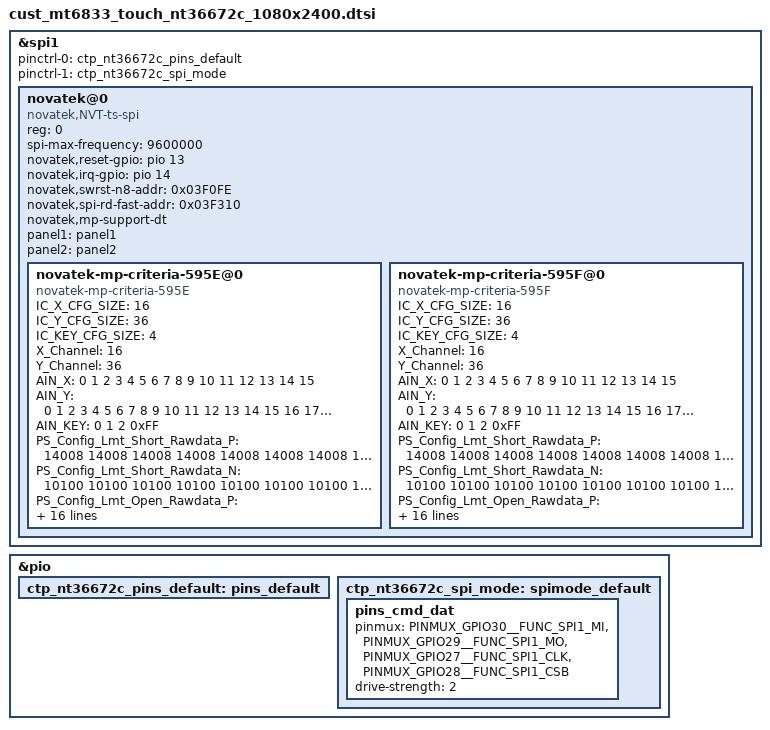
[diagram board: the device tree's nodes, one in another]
/*
 * Copyright (c) 2019 MediaTek Inc.
 *
 * This program is free software; you can redistribute it and/or modify
 * it under the terms of the GNU General Public License version 2 as
 * published by the Free Software Foundation.
 *
 * This program is distributed in the hope that it will be useful,
 * but WITHOUT ANY WARRANTY; without even the implied warranty of
 * MERCHANTABILITY or FITNESS FOR A PARTICULAR PURPOSE.  See the
 * GNU General Public License for more details.
 */

/* TOUCH start */
&spi1 {
	status = "okay";
	#address-cells = <1>;
	#size-cells = <0>;
	pinctrl-names = "default", "nt36672c_spi_mode";
	pinctrl-0 = <&ctp_nt36672c_pins_default>;
	pinctrl-1 = <&ctp_nt36672c_spi_mode>;

	/* Novatek device tree node */
	novatek@0 {
		compatible = "novatek,NVT-ts-spi";
		reg = <0>; //Same as CS ID
		status = "okay";
		//4800000,9600000,15000000,19200000
		spi-max-frequency = <9600000>;

		novatek,reset-gpio = <&pio 13 0x00>;
		novatek,irq-gpio = <&pio 14 0x00>;

		/* 525 */
		//novatek,swrst-n8-addr = <0x01F01A>;

		/* 672A, 525B, 675, 526 */
		novatek,swrst-n8-addr = <0x03F0FE>;
		novatek,spi-rd-fast-addr = <0x03F310>;

		/* MP */
		novatek,mp-support-dt;
		panel1 = <&panel1>;
		panel2 = <&panel2>;

		novatek-mp-criteria-595E@0 { //PID 为595E ，TM
			#address-cells = <1>;
			#size-cells = <0>;
			compatible = "novatek-mp-criteria-595E";

			/* MP Config */
			IC_X_CFG_SIZE = <16>;
			IC_Y_CFG_SIZE = <36>;
			IC_KEY_CFG_SIZE = <4>;
			X_Channel = <16>;
			Y_Channel = <36>;
			AIN_X = <0 1 2 3 4 5 6 7 8 9 10 11 12 13 14 15 >;
			AIN_Y = <0 1 2 3 4 5 6 7 8 9 10 11 12 13 14 15 16 17
			18 19 20 21 22 23 24 25 26 27 28 29 30 31 32 33 34 35>;
			AIN_KEY = <0 1 2 0xFF>;

			/* MP Criteria */
			PS_Config_Lmt_Short_Rawdata_P = <
			  14008 14008 14008 14008 14008 14008 14008 14008 14008 14008 14008 14008 14008 14008 14008 14008
			  14008 14008 14008 14008 14008 14008 14008 14008 14008 14008 14008 14008 14008 14008 14008 14008
			  14008 14008 14008 14008 14008 14008 14008 14008 14008 14008 14008 14008 14008 14008 14008 14008
			  14008 14008 14008 14008 14008 14008 14008 14008 14008 14008 14008 14008 14008 14008 14008 14008
			  14008 14008 14008 14008 14008 14008 14008 14008 14008 14008 14008 14008 14008 14008 14008 14008
			  14008 14008 14008 14008 14008 14008 14008 14008 14008 14008 14008 14008 14008 14008 14008 14008
			  14008 14008 14008 14008 14008 14008 14008 14008 14008 14008 14008 14008 14008 14008 14008 14008
			  14008 14008 14008 14008 14008 14008 14008 14008 14008 14008 14008 14008 14008 14008 14008 14008
			  14008 14008 14008 14008 14008 14008 14008 14008 14008 14008 14008 14008 14008 14008 14008 14008
			  14008 14008 14008 14008 14008 14008 14008 14008 14008 14008 14008 14008 14008 14008 14008 14008
			  14008 14008 14008 14008 14008 14008 14008 14008 14008 14008 14008 14008 14008 14008 14008 14008
			  14008 14008 14008 14008 14008 14008 14008 14008 14008 14008 14008 14008 14008 14008 14008 14008
			  14008 14008 14008 14008 14008 14008 14008 14008 14008 14008 14008 14008 14008 14008 14008 14008
			  14008 14008 14008 14008 14008 14008 14008 14008 14008 14008 14008 14008 14008 14008 14008 14008
			  14008 14008 14008 14008 14008 14008 14008 14008 14008 14008 14008 14008 14008 14008 14008 14008
			  14008 14008 14008 14008 14008 14008 14008 14008 14008 14008 14008 14008 14008 14008 14008 14008
			  14008 14008 14008 14008 14008 14008 14008 14008 14008 14008 14008 14008 14008 14008 14008 14008
			  14008 14008 14008 14008 14008 14008 14008 14008 14008 14008 14008 14008 14008 14008 14008 14008
			  14008 14008 14008 14008 14008 14008 14008 14008 14008 14008 14008 14008 14008 14008 14008 14008
			  14008 14008 14008 14008 14008 14008 14008 14008 14008 14008 14008 14008 14008 14008 14008 14008
			  14008 14008 14008 14008 14008 14008 14008 14008 14008 14008 14008 14008 14008 14008 14008 14008
			  14008 14008 14008 14008 14008 14008 14008 14008 14008 14008 14008 14008 14008 14008 14008 14008
			  14008 14008 14008 14008 14008 14008 14008 14008 14008 14008 14008 14008 14008 14008 14008 14008
			  14008 14008 14008 14008 14008 14008 14008 14008 14008 14008 14008 14008 14008 14008 14008 14008
			  14008 14008 14008 14008 14008 14008 14008 14008 14008 14008 14008 14008 14008 14008 14008 14008
			  14008 14008 14008 14008 14008 14008 14008 14008 14008 14008 14008 14008 14008 14008 14008 14008
			  14008 14008 14008 14008 14008 14008 14008 14008 14008 14008 14008 14008 14008 14008 14008 14008
			  14008 14008 14008 14008 14008 14008 14008 14008 14008 14008 14008 14008 14008 14008 14008 14008
			  14008 14008 14008 14008 14008 14008 14008 14008 14008 14008 14008 14008 14008 14008 14008 14008
			  14008 14008 14008 14008 14008 14008 14008 14008 14008 14008 14008 14008 14008 14008 14008 14008
			  14008 14008 14008 14008 14008 14008 14008 14008 14008 14008 14008 14008 14008 14008 14008 14008
			  14008 14008 14008 14008 14008 14008 14008 14008 14008 14008 14008 14008 14008 14008 14008 14008
			  14008 14008 14008 14008 14008 14008 14008 14008 14008 14008 14008 14008 14008 14008 14008 14008
			  14008 14008 14008 14008 14008 14008 14008 14008 14008 14008 14008 14008 14008 14008 14008 14008
			  14008 14008 14008 14008 14008 14008 14008 14008 14008 14008 14008 14008 14008 14008 14008 14008
			  14008 14008 14008 14008 14008 14008 14008 14008 14008 14008 14008 14008 14008 14008 14008 14008
			  14008 14008 14008>;

			PS_Config_Lmt_Short_Rawdata_N = <
			  10100 10100 10100 10100 10100 10100 10100 10100 10100 10100 10100 10100 10100 10100 10100 10100
			  10100 10100 10100 10100 10100 10100 10100 10100 10100 10100 10100 10100 10100 10100 10100 10100
			  10100 10100 10100 10100 10100 10100 10100 10100 10100 10100 10100 10100 10100 10100 10100 10100
			  10100 10100 10100 10100 10100 10100 10100 10100 10100 10100 10100 10100 10100 10100 10100 10100
			  10100 10100 10100 10100 10100 10100 10100 10100 10100 10100 10100 10100 10100 10100 10100 10100
			  10100 10100 10100 10100 10100 10100 10100 10100 10100 10100 10100 10100 10100 10100 10100 10100
			  10100 10100 10100 10100 10100 10100 10100 10100 10100 10100 10100 10100 10100 10100 10100 10100
			  10100 10100 10100 10100 10100 10100 10100 10100 10100 10100 10100 10100 10100 10100 10100 10100
			  10100 10100 10100 10100 10100 10100 10100 10100 10100 10100 10100 10100 10100 10100 10100 10100
			  10100 10100 10100 10100 10100 10100 10100 10100 10100 10100 10100 10100 10100 10100 10100 10100
			  10100 10100 10100 10100 10100 10100 10100 10100 10100 10100 10100 10100 10100 10100 10100 10100
			  10100 10100 10100 10100 10100 10100 10100 10100 10100 10100 10100 10100 10100 10100 10100 10100
			  10100 10100 10100 10100 10100 10100 10100 10100 10100 10100 10100 10100 10100 10100 10100 10100
			  10100 10100 10100 10100 10100 10100 10100 10100 10100 10100 10100 10100 10100 10100 10100 10100
			  10100 10100 10100 10100 10100 10100 10100 10100 10100 10100 10100 10100 10100 10100 10100 10100
			  10100 10100 10100 10100 10100 10100 10100 10100 10100 10100 10100 10100 10100 10100 10100 10100
			  10100 10100 10100 10100 10100 10100 10100 10100 10100 10100 10100 10100 10100 10100 10100 10100
			  10100 10100 10100 10100 10100 10100 10100 10100 10100 10100 10100 10100 10100 10100 10100 10100
			  10100 10100 10100 10100 10100 10100 10100 10100 10100 10100 10100 10100 10100 10100 10100 10100
			  10100 10100 10100 10100 10100 10100 10100 10100 10100 10100 10100 10100 10100 10100 10100 10100
			  10100 10100 10100 10100 10100 10100 10100 10100 10100 10100 10100 10100 10100 10100 10100 10100
			  10100 10100 10100 10100 10100 10100 10100 10100 10100 10100 10100 10100 10100 10100 10100 10100
			  10100 10100 10100 10100 10100 10100 10100 10100 10100 10100 10100 10100 10100 10100 10100 10100
			  10100 10100 10100 10100 10100 10100 10100 10100 10100 10100 10100 10100 10100 10100 10100 10100
			  10100 10100 10100 10100 10100 10100 10100 10100 10100 10100 10100 10100 10100 10100 10100 10100
			  10100 10100 10100 10100 10100 10100 10100 10100 10100 10100 10100 10100 10100 10100 10100 10100
			  10100 10100 10100 10100 10100 10100 10100 10100 10100 10100 10100 10100 10100 10100 10100 10100
			  10100 10100 10100 10100 10100 10100 10100 10100 10100 10100 10100 10100 10100 10100 10100 10100
			  10100 10100 10100 10100 10100 10100 10100 10100 10100 10100 10100 10100 10100 10100 10100 10100
			  10100 10100 10100 10100 10100 10100 10100 10100 10100 10100 10100 10100 10100 10100 10100 10100
			  10100 10100 10100 10100 10100 10100 10100 10100 10100 10100 10100 10100 10100 10100 10100 10100
			  10100 10100 10100 10100 10100 10100 10100 10100 10100 10100 10100 10100 10100 10100 10100 10100
			  10100 10100 10100 10100 10100 10100 10100 10100 10100 10100 10100 10100 10100 10100 10100 10100
			  10100 10100 10100 10100 10100 10100 10100 10100 10100 10100 10100 10100 10100 10100 10100 10100
			  10100 10100 10100 10100 10100 10100 10100 10100 10100 10100 10100 10100 10100 10100 10100 10100
			  10100 10100 10100 10100 10100 10100 10100 10100 10100 10100 10100 10100 10100 10100 10100 10100
			  10000 10000 10000>;

			PS_Config_Lmt_Open_Rawdata_P = <
			  4208 4327 4419 4670 4583 4650 4572 4468 4379 4575 4583 4621 4639 4460 4335 4284
			  4403 4543 4580 4701 4624 4684 4590 4540 4403 4593 4607 4646 4656 4638 4536 4506
			  4540 4594 4648 4797 4727 4765 4747 4775 4701 4746 4695 4734 4762 4687 4600 4572
			  4578 4587 4683 4841 4761 4799 4771 4796 4727 4740 4716 4757 4769 4699 4600 4580
			  4628 4698 4723 4895 4831 4872 4821 4855 4797 4866 4771 4828 4816 4741 4635 4622
			  4636 4699 4697 4898 4844 4895 4832 4866 4792 4855 4720 4813 4793 4719 4624 4607
			  4655 4720 4778 4918 4873 4932 4860 4893 4855 4912 4834 4858 4820 4767 4649 4636
			  4649 4722 4785 4879 4888 4950 4866 4894 4872 4918 4846 4844 4813 4754 4650 4625
			  4719 4783 4838 4979 4964 5010 4940 4957 4963 4999 4928 4974 4867 4811 4713 4674
			  4734 4789 4842 4991 4951 5020 4947 4954 4970 5003 4923 4977 4832 4796 4691 4660
			  4730 4804 4848 5013 5017 5017 4963 4998 4988 5047 4956 5027 4883 4782 4701 4681
			  4769 4845 4879 5044 5052 5101 4996 5017 4984 5042 4954 5034 4886 4832 4704 4680
			  4796 4858 4911 5062 5104 5160 5007 5044 5031 5079 5012 5061 4907 4862 4690 4684
			  4782 4846 4904 5038 5096 5154 5048 5020 5055 5104 5037 5097 4907 4872 4748 4691
			  4849 4909 4963 5100 5160 5222 5132 5052 5129 5159 5077 5145 4963 4894 4788 4680
			  4851 4915 4957 5086 5161 5219 5145 5115 5154 5175 5100 5166 4958 4895 4782 4712
			  4860 4932 4946 5086 5167 5243 5139 5133 5181 5220 5124 5202 4975 4918 4783 4732
			  4855 4932 4930 5073 5161 5234 5145 5139 5163 5205 5111 5178 4956 4904 4750 4711
			  4758 4722 4662 4669 4579 4606 4594 4653 4529 4639 4617 4634 4638 4740 4741 4907
			  4762 4751 4669 4677 4596 4625 4606 4673 4534 4632 4629 4646 4655 4750 4744 4901
			  4771 4778 4698 4699 4622 4648 4631 4688 4573 4678 4671 4690 4687 4793 4775 4890
			  4774 4778 4701 4701 4614 4643 4632 4678 4562 4678 4680 4701 4698 4792 4762 4881
			  4786 4813 4716 4716 4652 4666 4650 4692 4597 4704 4690 4746 4732 4804 4781 4881
			  4797 4832 4733 4750 4660 4677 4666 4706 4603 4690 4685 4736 4727 4792 4771 4860
			  4769 4821 4727 4736 4655 4676 4655 4697 4618 4713 4699 4747 4741 4824 4790 4873
			  4778 4841 4743 4751 4669 4708 4677 4725 4624 4698 4685 4734 4729 4811 4776 4837
			  4760 4827 4741 4747 4667 4688 4681 4723 4643 4716 4720 4760 4761 4831 4820 4845
			  4758 4825 4744 4744 4670 4697 4685 4720 4628 4692 4687 4730 4719 4799 4778 4795
			  4772 4866 4765 4796 4699 4732 4718 4757 4650 4723 4698 4758 4744 4820 4797 4797
			  4743 4823 4734 4768 4674 4702 4698 4729 4627 4691 4660 4716 4709 4779 4753 4757
			  4722 4817 4748 4769 4676 4716 4698 4726 4632 4709 4691 4726 4718 4806 4743 4750
			  4356 4796 4370 4762 4312 4725 4326 4716 4281 4708 4314 4720 4344 4797 4359 4736
			  4383 4440 4405 4428 4351 4394 4366 4387 4317 4377 4344 4382 4369 4432 4375 4384
			  4376 4428 4403 4429 4345 4387 4359 4383 4324 4386 4338 4383 4363 4426 4363 4375
			  4225 4348 4320 4349 4271 4314 4279 4312 4250 4323 4260 4313 4292 4356 4279 4239
			  3880 3943 3990 4382 4295 4337 4303 4338 4254 4331 4265 4312 4295 4018 3858 3876
			  5120  5120  5120>;

			PS_Config_Lmt_Open_Rawdata_N = <
			  1803 1854 1894 2001 1964 1993 1959 1915 1876 1960 1964 1980 1988 1911 1858 1836
			  1887 1947 1963 2014 1981 2007 1967 1945 1887 1968 1974 1991 1995 1987 1944 1931
			  1945 1969 1992 2056 2026 2042 2034 2046 2014 2034 2012 2029 2041 2008 1971 1959
			  1962 1966 2007 2074 2040 2056 2044 2055 2026 2031 2021 2038 2044 2014 1971 1963
			  1983 2013 2024 2098 2070 2088 2066 2080 2056 2085 2044 2069 2064 2032 1986 1981
			  1987 2014 2013 2099 2076 2098 2071 2085 2053 2080 2023 2062 2054 2022 1981 1974
			  1995 2023 2047 2107 2088 2113 2083 2097 2080 2105 2071 2082 2065 2043 1992 1987
			  1992 2023 2050 2091 2095 2121 2085 2097 2088 2107 2077 2076 2062 2037 1993 1982
			  2022 2050 2073 2134 2127 2147 2117 2124 2127 2142 2112 2131 2086 2062 2020 2003
			  2029 2052 2075 2139 2122 2151 2120 2123 2130 2144 2110 2133 2071 2055 2010 1997
			  2027 2059 2077 2148 2150 2150 2127 2142 2137 2163 2124 2154 2092 2049 2014 2006
			  2044 2076 2091 2161 2165 2186 2141 2150 2136 2161 2123 2157 2094 2071 2016 2005
			  2055 2082 2104 2169 2187 2211 2146 2161 2156 2176 2148 2169 2103 2083 2010 2007
			  2049 2077 2101 2159 2184 2209 2163 2151 2166 2187 2158 2184 2103 2088 2035 2010
			  2078 2104 2127 2185 2211 2238 2199 2165 2198 2211 2176 2205 2127 2097 2052 2005
			  2079 2106 2124 2179 2212 2236 2205 2192 2209 2218 2185 2214 2125 2098 2049 2019
			  2083 2113 2119 2179 2214 2247 2202 2200 2220 2237 2196 2229 2132 2107 2050 2028
			  2080 2113 2113 2174 2212 2243 2205 2202 2212 2230 2190 2219 2124 2101 2035 2019
			  2039 2023 1998 2001 1962 1974 1969 1994 1941 1988 1978 1986 1987 2031 2032 2103
			  2041 2036 2001 2004 1969 1982 1974 2002 1943 1985 1984 1991 1995 2035 2033 2100
			  2044 2047 2013 2014 1981 1992 1984 2009 1960 2005 2002 2010 2008 2054 2046 2095
			  2046 2047 2014 2014 1977 1990 1985 2005 1955 2005 2005 2014 2013 2053 2041 2092
			  2051 2062 2021 2021 1993 1999 1993 2011 1970 2016 2010 2034 2028 2059 2049 2092
			  2056 2071 2028 2035 1997 2004 1999 2017 1972 2010 2008 2029 2026 2053 2044 2083
			  2044 2066 2026 2029 1995 2004 1995 2013 1979 2020 2014 2034 2032 2067 2053 2088
			  2047 2074 2032 2036 2001 2017 2004 2025 1981 2013 2008 2029 2026 2062 2047 2073
			  2040 2068 2032 2034 2000 2009 2006 2024 1990 2021 2023 2040 2040 2070 2065 2076
			  2039 2068 2033 2033 2001 2013 2008 2023 1983 2011 2008 2027 2022 2056 2047 2055
			  2045 2085 2042 2055 2014 2028 2022 2038 1993 2024 2013 2039 2033 2065 2056 2056
			  2032 2067 2029 2043 2003 2015 2013 2026 1983 2010 1997 2021 2018 2048 2037 2038
			  2023 2064 2035 2044 2004 2021 2013 2025 1985 2018 2010 2025 2022 2059 2032 2035
			  1867 2055 1873 2041 1848 2025 1854 2021 1834 2017 1849 2023 1861 2056 1868 2029
			  1878 1903 1888 1897 1864 1883 1871 1880 1850 1876 1861 1878 1872 1899 1875 1879
			  1875 1897 1887 1898 1862 1880 1868 1878 1853 1879 1859 1878 1870 1897 1870 1875
			  1810 1863 1851 1864 1830 1849 1834 1848 1821 1852 1825 1848 1839 1867 1834 1816
			  1663 1690 1710 1878 1840 1858 1844 1859 1823 1856 1828 1848 1840 1722 1653 1661
			  (-511) (-511) (-511)>;

			PS_Config_Lmt_FW_Rawdata_P = <
			  1122 1107 1121 1108 1128 1117 1127 1128 1124 1107 1106 1111 1104 1136 1103 1127
			  1120 1124 1120 1124 1113 1122 1120 1122 1127 1128 1125 1121 1125 1128 1129 1111
			  1103 1128 1127 1121 1132 1124 1129 1108 1125 1124 1122 1118 1125 1124 1120 1129
			  1121 1111 1120 1117 1114 1118 1117 1122 1127 1125 1113 1127 1117 1111 1115 1124
			  1121 1120 1113 1117 1114 1115 1117 1128 1122 1124 1128 1135 1125 1122 1114 1129
			  1108 1122 1125 1122 1120 1124 1122 1113 1122 1124 1122 1122 1120 1127 1122 1106
			  1127 1115 1118 1120 1120 1118 1118 1122 1113 1110 1108 1108 1114 1113 1114 1107
			  1111 1121 1113 1113 1113 1114 1113 1127 1127 1131 1141 1138 1138 1124 1118 1103
			  1129 1121 1121 1115 1117 1117 1117 1124 1115 1111 1120 1117 1118 1121 1124 1117
			  1113 1113 1115 1120 1121 1122 1120 1113 1108 1110 1121 1121 1118 1129 1122 1108
			  1113 1108 1111 1106 1113 1114 1111 1124 1121 1120 1131 1125 1127 1121 1113 1121
			  1121 1125 1127 1118 1120 1132 1122 1113 1117 1113 1118 1120 1120 1120 1121 1121
			  1104 1120 1118 1114 1114 1108 1113 1121 1120 1124 1122 1120 1121 1118 1117 1115
			  1114 1114 1115 1120 1122 1114 1117 1122 1111 1110 1120 1120 1122 1121 1121 1113
			  1132 1120 1122 1125 1122 1131 1129 1108 1121 1118 1115 1113 1114 1124 1124 1121
			  1121 1120 1121 1113 1118 1117 1117 1118 1111 1108 1115 1110 1117 1128 1129 1114
			  1113 1122 1120 1113 1114 1118 1111 1128 1118 1128 1127 1120 1110 1111 1113 1124
			  1121 1111 1122 1122 1121 1114 1120 1122 1104 1114 1115 1110 1127 1127 1125 1122
			  1114 1124 1128 1121 1128 1111 1115 1118 1118 1115 1117 1117 1115 1120 1113 1117
			  1108 1113 1115 1118 1111 1115 1115 1122 1106 1120 1127 1120 1118 1118 1115 1120
			  1125 1114 1122 1107 1122 1110 1101 1103 1127 1125 1124 1110 1113 1108 1108 1128
			  1111 1128 1117 1124 1120 1125 1127 1125 1113 1124 1122 1127 1125 1124 1121 1117
			  1114 1122 1120 1125 1121 1120 1118 1117 1127 1127 1127 1121 1127 1124 1118 1111
			  1118 1114 1113 1114 1114 1113 1120 1121 1113 1124 1125 1122 1127 1125 1120 1117
			  1117 1111 1114 1106 1120 1117 1110 1117 1121 1120 1117 1115 1115 1117 1113 1127
			  1120 1113 1113 1118 1118 1120 1122 1115 1122 1120 1120 1117 1121 1120 1120 1121
			  1110 1124 1127 1127 1121 1124 1127 1122 1107 1110 1107 1113 1114 1115 1117 1122
			  1121 1121 1121 1120 1118 1120 1113 1110 1114 1122 1121 1117 1115 1120 1110 1110
			  1129 1108 1108 1111 1113 1113 1121 1124 1114 1114 1113 1117 1115 1111 1113 1128
			  1113 1122 1127 1121 1121 1121 1127 1120 1121 1124 1122 1122 1120 1121 1122 1114
			  1115 1117 1107 1124 1122 1124 1114 1111 1118 1122 1120 1114 1111 1118 1115 1127
			  1108 1122 1124 1121 1128 1124 1127 1122 1108 1110 1127 1113 1131 1117 1120 1115
			  1120 1124 1128 1117 1128 1122 1128 1124 1121 1118 1121 1125 1125 1118 1121 1115
			  1117 1115 1118 1114 1115 1114 1121 1124 1125 1125 1124 1125 1120 1117 1114 1107
			  1128 1118 1118 1115 1117 1118 1117 1118 1118 1117 1117 1117 1120 1115 1120 1115
			  1117 1114 1107 1121 1122 1124 1125 1117 1111 1127 1128 1131 1128 1107 1106 1113
			  3840 3840  3840>;

			PS_Config_Lmt_FW_Rawdata_N = <
			  481 474 480 475 483 478 483 483 481 474 474 476 473 487 472 483
			  480 481 480 481 477 481 480 481 483 483 482 480 482 483 484 476
			  472 483 483 480 485 481 484 475 482 481 481 479 482 481 480 484
			  480 476 480 478 477 479 478 481 483 482 477 483 478 476 478 481
			  480 480 477 478 477 478 478 483 481 481 483 486 482 481 477 484
			  475 481 482 481 480 481 481 477 481 481 481 481 480 483 481 474
			  483 478 479 480 480 479 479 481 477 475 475 475 477 477 477 474
			  476 480 477 477 477 477 477 483 483 484 489 487 487 481 479 472
			  484 480 480 478 478 478 478 481 478 476 480 478 479 480 481 478
			  477 477 478 480 480 481 480 477 475 475 480 480 479 484 481 475
			  477 475 476 474 477 477 476 481 480 480 484 482 483 480 477 480
			  480 482 483 479 480 485 481 477 478 477 479 480 480 480 480 480
			  473 480 479 477 477 475 477 480 480 481 481 480 480 479 478 478
			  477 477 478 480 481 477 478 481 476 475 480 480 481 480 480 477
			  485 480 481 482 481 484 484 475 480 479 478 477 477 481 481 480
			  480 480 480 477 479 478 478 479 476 475 478 475 478 483 484 477
			  477 481 480 477 477 479 476 483 479 483 483 480 475 476 477 481
			  480 476 481 481 480 477 480 481 473 477 478 475 483 483 482 481
			  477 481 483 480 483 476 478 479 479 478 478 478 478 480 477 478
			  475 477 478 479 476 478 478 481 474 480 483 480 479 479 478 480
			  482 477 481 474 481 475 472 472 483 482 481 475 477 475 475 483
			  476 483 478 481 480 482 483 482 477 481 481 483 482 481 480 478
			  477 481 480 482 480 480 479 478 483 483 483 480 483 481 479 476
			  479 477 477 477 477 477 480 480 477 481 482 481 483 482 480 478
			  478 476 477 474 480 478 475 478 480 480 478 478 478 478 477 483
			  480 477 477 479 479 480 481 478 481 480 480 478 480 480 480 480
			  475 481 483 483 480 481 483 481 474 475 474 477 477 478 478 481
			  480 480 480 480 479 480 477 475 477 481 480 478 478 480 475 475
			  484 475 475 476 477 477 480 481 477 477 477 478 478 476 477 483
			  477 481 483 480 480 480 483 480 480 481 481 481 480 480 481 477
			  478 478 474 481 481 481 477 476 479 481 480 477 476 479 478 483
			  475 481 481 480 483 481 483 481 475 475 483 477 484 478 480 478
			  480 481 483 478 483 481 483 481 480 479 480 482 482 479 480 478
			  478 478 479 477 478 477 480 481 482 482 481 482 480 478 477 474
			  483 479 479 478 478 479 478 479 479 478 478 478 480 478 480 478
			  478 477 474 480 481 481 482 478 476 483 483 484 483 474 474 477
			  240 240 240>;

			PS_Config_Lmt_FW_CC_P = <
			  53 53 55 55 55 55 55 55 55 55 55 55 55 55 53 53
			  55 55 55 55 55 55 55 55 55 55 55 55 55 55 55 55
			  55 53 53 53 53 53 53 55 55 55 55 55 55 55 55 55
			  55 55 55 55 55 55 55 55 55 55 55 55 55 55 55 55
			  55 53 55 55 53 55 55 55 55 55 55 55 55 55 55 55
			  56 55 55 55 55 55 55 56 55 55 55 55 55 55 55 55
			  55 55 53 55 53 55 55 55 55 55 55 55 55 53 53 55
			  55 55 55 55 55 55 55 56 55 55 55 55 55 53 53 55
			  55 53 55 55 55 55 55 55 55 55 55 55 55 55 53 55
			  55 55 55 55 55 55 55 56 55 55 55 55 55 55 53 55
			  55 55 53 55 55 55 55 55 55 55 55 55 55 55 55 55
			  55 55 55 55 55 55 55 56 55 55 55 55 55 55 53 55
			  55 55 55 55 55 55 55 55 55 55 55 55 55 55 55 55
			  55 55 55 55 55 55 55 56 55 55 55 55 55 55 53 55
			  55 55 55 55 55 55 55 55 55 55 55 55 55 55 55 55
			  55 55 55 55 55 56 55 56 55 55 55 55 55 55 55 56
			  55 55 55 55 55 55 55 56 55 55 55 55 55 55 55 55
			  55 55 55 55 55 56 55 56 55 55 55 55 55 53 53 56
			  55 53 53 53 53 53 53 53 55 55 55 55 55 53 53 55
			  56 55 55 55 55 55 55 55 55 55 55 55 55 55 55 55
			  55 53 53 53 53 53 53 55 55 55 55 55 55 55 55 55
			  56 55 55 55 55 55 55 55 55 55 55 53 55 55 55 55
			  55 53 53 53 53 53 55 55 55 55 55 55 55 55 55 55
			  55 55 55 55 53 53 55 55 55 53 55 53 53 53 53 55
			  55 53 53 53 53 53 53 55 55 55 55 55 55 55 55 55
			  56 55 55 55 55 55 55 55 55 55 55 53 53 55 55 55
			  55 53 53 53 53 53 53 53 55 55 55 55 55 55 55 55
			  56 55 55 55 55 55 55 55 55 55 55 55 55 55 55 55
			  55 55 55 55 55 55 55 55 55 55 55 55 55 55 55 55
			  55 55 55 53 53 53 55 55 55 53 55 53 53 53 53 55
			  55 53 53 53 53 53 53 55 55 55 55 55 55 55 55 55
			  55 55 55 55 55 55 55 55 55 55 55 55 55 55 53 56
			  55 53 53 53 55 53 53 55 55 55 55 55 55 55 53 55
			  55 55 55 55 55 55 55 55 55 55 53 53 55 55 53 55
			  53 53 53 53 53 53 53 53 53 53 53 53 53 53 53 55
			  53 53 53 55 55 55 55 55 55 55 55 55 55 53 53 53
			  314 314 314>;

			PS_Config_Lmt_FW_CC_N = <
			  24 24 24 24 24 24 24 24 24 24 24 24 24 24 24 24
			  24 24 24 24 24 24 24 24 24 24 24 24 24 24 24 24
			  24 24 24 24 24 24 24 24 24 24 24 24 24 24 24 24
			  24 24 24 24 24 24 24 24 24 24 24 24 24 24 24 24
			  24 24 24 24 24 24 24 24 24 24 24 24 24 24 24 24
			  25 24 24 24 24 24 24 25 24 24 24 24 24 24 24 24
			  24 24 24 24 24 24 24 24 24 24 24 24 24 24 24 24
			  24 24 24 24 24 24 24 25 24 24 24 24 24 24 24 24
			  24 24 24 24 24 24 24 24 24 24 24 24 24 24 24 24
			  24 24 24 24 24 24 24 25 24 24 24 24 24 24 24 24
			  24 24 24 24 24 24 24 24 24 24 24 24 24 24 24 24
			  24 24 24 24 24 24 24 25 24 24 24 24 24 24 24 24
			  24 24 24 24 24 24 24 24 24 24 24 24 24 24 24 24
			  24 24 24 24 24 24 24 25 24 24 24 24 24 24 24 24
			  24 24 24 24 24 24 24 24 24 24 24 24 24 24 24 24
			  24 24 24 24 24 25 24 25 24 24 24 24 24 24 24 25
			  24 24 24 24 24 24 24 25 24 24 24 24 24 24 24 24
			  24 24 24 24 24 25 24 25 24 24 24 24 24 24 24 25
			  24 24 24 24 24 24 24 24 24 24 24 24 24 24 24 24
			  25 24 24 24 24 24 24 24 24 24 24 24 24 24 24 24
			  24 24 24 24 24 24 24 24 24 24 24 24 24 24 24 24
			  25 24 24 24 24 24 24 24 24 24 24 24 24 24 24 24
			  24 24 24 24 24 24 24 24 24 24 24 24 24 24 24 24
			  24 24 24 24 24 24 24 24 24 24 24 24 24 24 24 24
			  24 24 24 24 24 24 24 24 24 24 24 24 24 24 24 24
			  25 24 24 24 24 24 24 24 24 24 24 24 24 24 24 24
			  24 24 24 24 24 24 24 24 24 24 24 24 24 24 24 24
			  25 24 24 24 24 24 24 24 24 24 24 24 24 24 24 24
			  24 24 24 24 24 24 24 24 24 24 24 24 24 24 24 24
			  24 24 24 24 24 24 24 24 24 24 24 24 24 24 24 24
			  24 24 24 24 24 24 24 24 24 24 24 24 24 24 24 24
			  24 24 24 24 24 24 24 24 24 24 24 24 24 24 24 25
			  24 24 24 24 24 24 24 24 24 24 24 24 24 24 24 24
			  24 24 24 24 24 24 24 24 24 24 24 24 24 24 24 24
			  24 24 24 24 24 24 24 24 24 24 24 24 24 24 24 24
			  24 24 24 24 24 24 24 24 24 24 24 24 24 24 24 24
			  0 0 0>;

			PS_Config_Lmt_FW_Diff_P = <
			  50 50 50 50 50 50 50 50 50 50 50 50 50 50 50 50
			  50 50 50 50 50 50 50 50 50 50 50 50 50 50 50 50
			  50 50 50 50 50 50 50 50 50 50 50 50 50 50 50 50
			  50 50 50 50 50 50 50 50 50 50 50 50 50 50 50 50
			  50 50 50 50 50 50 50 50 50 50 50 50 50 50 50 50
			  50 50 50 50 50 50 50 50 50 50 50 50 50 50 50 50
			  50 50 50 50 50 50 50 50 50 50 50 50 50 50 50 50
			  50 50 50 50 50 50 50 50 50 50 50 50 50 50 50 50
			  50 50 50 50 50 50 50 50 50 50 50 50 50 50 50 50
			  50 50 50 50 50 50 50 50 50 50 50 50 50 50 50 50
			  50 50 50 50 50 50 50 50 50 50 50 50 50 50 50 50
			  50 50 50 50 50 50 50 50 50 50 50 50 50 50 50 50
			  50 50 50 50 50 50 50 50 50 50 50 50 50 50 50 50
			  50 50 50 50 50 50 50 50 50 50 50 50 50 50 50 50
			  50 50 50 50 50 50 50 50 50 50 50 50 50 50 50 50
			  50 50 50 50 50 50 50 50 50 50 50 50 50 50 50 50
			  50 50 50 50 50 50 50 50 50 50 50 50 50 50 50 50
			  50 50 50 50 50 50 50 50 50 50 50 50 50 50 50 50
			  50 50 50 50 50 50 50 50 50 50 50 50 50 50 50 50
			  50 50 50 50 50 50 50 50 50 50 50 50 50 50 50 50
			  50 50 50 50 50 50 50 50 50 50 50 50 50 50 50 50
			  50 50 50 50 50 50 50 50 50 50 50 50 50 50 50 50
			  50 50 50 50 50 50 50 50 50 50 50 50 50 50 50 50
			  50 50 50 50 50 50 50 50 50 50 50 50 50 50 50 50
			  50 50 50 50 50 50 50 50 50 50 50 50 50 50 50 50
			  50 50 50 50 50 50 50 50 50 50 50 50 50 50 50 50
			  50 50 50 50 50 50 50 50 50 50 50 50 50 50 50 50
			  50 50 50 50 50 50 50 50 50 50 50 50 50 50 50 50
			  50 50 50 50 50 50 50 50 50 50 50 50 50 50 50 50
			  50 50 50 50 50 50 50 50 50 50 50 50 50 50 50 50
			  50 50 50 50 50 50 50 50 50 50 50 50 50 50 50 50
			  50 50 50 50 50 50 50 50 50 50 50 50 50 50 50 50
			  50 50 50 50 50 50 50 50 50 50 50 50 50 50 50 50
			  50 50 50 50 50 50 50 50 50 50 50 50 50 50 50 50
			  50 50 50 50 50 50 50 50 50 50 50 50 50 50 50 50
			  50 50 50 50 50 50 50 50 50 50 50 50 50 50 50 50
			  75 75 75>;

			PS_Config_Lmt_FW_Diff_N = <
			  (-50) (-50) (-50) (-50) (-50) (-50) (-50) (-50) (-50) (-50) (-50) (-50) (-50) (-50) (-50) (-50)
			  (-50) (-50) (-50) (-50) (-50) (-50) (-50) (-50) (-50) (-50) (-50) (-50) (-50) (-50) (-50) (-50)
			  (-50) (-50) (-50) (-50) (-50) (-50) (-50) (-50) (-50) (-50) (-50) (-50) (-50) (-50) (-50) (-50)
			  (-50) (-50) (-50) (-50) (-50) (-50) (-50) (-50) (-50) (-50) (-50) (-50) (-50) (-50) (-50) (-50)
			  (-50) (-50) (-50) (-50) (-50) (-50) (-50) (-50) (-50) (-50) (-50) (-50) (-50) (-50) (-50) (-50)
			  (-50) (-50) (-50) (-50) (-50) (-50) (-50) (-50) (-50) (-50) (-50) (-50) (-50) (-50) (-50) (-50)
			  (-50) (-50) (-50) (-50) (-50) (-50) (-50) (-50) (-50) (-50) (-50) (-50) (-50) (-50) (-50) (-50)
			  (-50) (-50) (-50) (-50) (-50) (-50) (-50) (-50) (-50) (-50) (-50) (-50) (-50) (-50) (-50) (-50)
			  (-50) (-50) (-50) (-50) (-50) (-50) (-50) (-50) (-50) (-50) (-50) (-50) (-50) (-50) (-50) (-50)
			  (-50) (-50) (-50) (-50) (-50) (-50) (-50) (-50) (-50) (-50) (-50) (-50) (-50) (-50) (-50) (-50)
			  (-50) (-50) (-50) (-50) (-50) (-50) (-50) (-50) (-50) (-50) (-50) (-50) (-50) (-50) (-50) (-50)
			  (-50) (-50) (-50) (-50) (-50) (-50) (-50) (-50) (-50) (-50) (-50) (-50) (-50) (-50) (-50) (-50)
			  (-50) (-50) (-50) (-50) (-50) (-50) (-50) (-50) (-50) (-50) (-50) (-50) (-50) (-50) (-50) (-50)
			  (-50) (-50) (-50) (-50) (-50) (-50) (-50) (-50) (-50) (-50) (-50) (-50) (-50) (-50) (-50) (-50)
			  (-50) (-50) (-50) (-50) (-50) (-50) (-50) (-50) (-50) (-50) (-50) (-50) (-50) (-50) (-50) (-50)
			  (-50) (-50) (-50) (-50) (-50) (-50) (-50) (-50) (-50) (-50) (-50) (-50) (-50) (-50) (-50) (-50)
			  (-50) (-50) (-50) (-50) (-50) (-50) (-50) (-50) (-50) (-50) (-50) (-50) (-50) (-50) (-50) (-50)
			  (-50) (-50) (-50) (-50) (-50) (-50) (-50) (-50) (-50) (-50) (-50) (-50) (-50) (-50) (-50) (-50)
			  (-50) (-50) (-50) (-50) (-50) (-50) (-50) (-50) (-50) (-50) (-50) (-50) (-50) (-50) (-50) (-50)
			  (-50) (-50) (-50) (-50) (-50) (-50) (-50) (-50) (-50) (-50) (-50) (-50) (-50) (-50) (-50) (-50)
			  (-50) (-50) (-50) (-50) (-50) (-50) (-50) (-50) (-50) (-50) (-50) (-50) (-50) (-50) (-50) (-50)
			  (-50) (-50) (-50) (-50) (-50) (-50) (-50) (-50) (-50) (-50) (-50) (-50) (-50) (-50) (-50) (-50)
			  (-50) (-50) (-50) (-50) (-50) (-50) (-50) (-50) (-50) (-50) (-50) (-50) (-50) (-50) (-50) (-50)
			  (-50) (-50) (-50) (-50) (-50) (-50) (-50) (-50) (-50) (-50) (-50) (-50) (-50) (-50) (-50) (-50)
			  (-50) (-50) (-50) (-50) (-50) (-50) (-50) (-50) (-50) (-50) (-50) (-50) (-50) (-50) (-50) (-50)
			  (-50) (-50) (-50) (-50) (-50) (-50) (-50) (-50) (-50) (-50) (-50) (-50) (-50) (-50) (-50) (-50)
			  (-50) (-50) (-50) (-50) (-50) (-50) (-50) (-50) (-50) (-50) (-50) (-50) (-50) (-50) (-50) (-50)
			  (-50) (-50) (-50) (-50) (-50) (-50) (-50) (-50) (-50) (-50) (-50) (-50) (-50) (-50) (-50) (-50)
			  (-50) (-50) (-50) (-50) (-50) (-50) (-50) (-50) (-50) (-50) (-50) (-50) (-50) (-50) (-50) (-50)
			  (-50) (-50) (-50) (-50) (-50) (-50) (-50) (-50) (-50) (-50) (-50) (-50) (-50) (-50) (-50) (-50)
			  (-50) (-50) (-50) (-50) (-50) (-50) (-50) (-50) (-50) (-50) (-50) (-50) (-50) (-50) (-50) (-50)
			  (-50) (-50) (-50) (-50) (-50) (-50) (-50) (-50) (-50) (-50) (-50) (-50) (-50) (-50) (-50) (-50)
			  (-50) (-50) (-50) (-50) (-50) (-50) (-50) (-50) (-50) (-50) (-50) (-50) (-50) (-50) (-50) (-50)
			  (-50) (-50) (-50) (-50) (-50) (-50) (-50) (-50) (-50) (-50) (-50) (-50) (-50) (-50) (-50) (-50)
			  (-50) (-50) (-50) (-50) (-50) (-50) (-50) (-50) (-50) (-50) (-50) (-50) (-50) (-50) (-50) (-50)
			  (-50) (-50) (-50) (-50) (-50) (-50) (-50) (-50) (-50) (-50) (-50) (-50) (-50) (-50) (-50) (-50)
			  (-75) (-75) (-75)>;
			PS_Config_Diff_Test_Frame = <50>;
		};
		novatek-mp-criteria-595F@0 { //PID 为595F ，COST
			#address-cells = <1>;
			#size-cells = <0>;
			compatible = "novatek-mp-criteria-595F";

			/* MP Config */
			IC_X_CFG_SIZE = <16>;
			IC_Y_CFG_SIZE = <36>;
			IC_KEY_CFG_SIZE = <4>;
			X_Channel = <16>;
			Y_Channel = <36>;
			AIN_X = <0 1 2 3 4 5 6 7 8 9 10 11 12 13 14 15 >;
			AIN_Y = <0 1 2 3 4 5 6 7 8 9 10 11 12 13 14 15 16 17
			18 19 20 21 22 23 24 25 26 27 28 29 30 31 32 33 34 35>;
			AIN_KEY = <0 1 2 0xFF>;

			/* MP Criteria */
			PS_Config_Lmt_Short_Rawdata_P = <
			  14008 14008 14008 14008 14008 14008 14008 14008 14008 14008 14008 14008 14008 14008 14008 14008
			  14008 14008 14008 14008 14008 14008 14008 14008 14008 14008 14008 14008 14008 14008 14008 14008
			  14008 14008 14008 14008 14008 14008 14008 14008 14008 14008 14008 14008 14008 14008 14008 14008
			  14008 14008 14008 14008 14008 14008 14008 14008 14008 14008 14008 14008 14008 14008 14008 14008
			  14008 14008 14008 14008 14008 14008 14008 14008 14008 14008 14008 14008 14008 14008 14008 14008
			  14008 14008 14008 14008 14008 14008 14008 14008 14008 14008 14008 14008 14008 14008 14008 14008
			  14008 14008 14008 14008 14008 14008 14008 14008 14008 14008 14008 14008 14008 14008 14008 14008
			  14008 14008 14008 14008 14008 14008 14008 14008 14008 14008 14008 14008 14008 14008 14008 14008
			  14008 14008 14008 14008 14008 14008 14008 14008 14008 14008 14008 14008 14008 14008 14008 14008
			  14008 14008 14008 14008 14008 14008 14008 14008 14008 14008 14008 14008 14008 14008 14008 14008
			  14008 14008 14008 14008 14008 14008 14008 14008 14008 14008 14008 14008 14008 14008 14008 14008
			  14008 14008 14008 14008 14008 14008 14008 14008 14008 14008 14008 14008 14008 14008 14008 14008
			  14008 14008 14008 14008 14008 14008 14008 14008 14008 14008 14008 14008 14008 14008 14008 14008
			  14008 14008 14008 14008 14008 14008 14008 14008 14008 14008 14008 14008 14008 14008 14008 14008
			  14008 14008 14008 14008 14008 14008 14008 14008 14008 14008 14008 14008 14008 14008 14008 14008
			  14008 14008 14008 14008 14008 14008 14008 14008 14008 14008 14008 14008 14008 14008 14008 14008
			  14008 14008 14008 14008 14008 14008 14008 14008 14008 14008 14008 14008 14008 14008 14008 14008
			  14008 14008 14008 14008 14008 14008 14008 14008 14008 14008 14008 14008 14008 14008 14008 14008
			  14008 14008 14008 14008 14008 14008 14008 14008 14008 14008 14008 14008 14008 14008 14008 14008
			  14008 14008 14008 14008 14008 14008 14008 14008 14008 14008 14008 14008 14008 14008 14008 14008
			  14008 14008 14008 14008 14008 14008 14008 14008 14008 14008 14008 14008 14008 14008 14008 14008
			  14008 14008 14008 14008 14008 14008 14008 14008 14008 14008 14008 14008 14008 14008 14008 14008
			  14008 14008 14008 14008 14008 14008 14008 14008 14008 14008 14008 14008 14008 14008 14008 14008
			  14008 14008 14008 14008 14008 14008 14008 14008 14008 14008 14008 14008 14008 14008 14008 14008
			  14008 14008 14008 14008 14008 14008 14008 14008 14008 14008 14008 14008 14008 14008 14008 14008
			  14008 14008 14008 14008 14008 14008 14008 14008 14008 14008 14008 14008 14008 14008 14008 14008
			  14008 14008 14008 14008 14008 14008 14008 14008 14008 14008 14008 14008 14008 14008 14008 14008
			  14008 14008 14008 14008 14008 14008 14008 14008 14008 14008 14008 14008 14008 14008 14008 14008
			  14008 14008 14008 14008 14008 14008 14008 14008 14008 14008 14008 14008 14008 14008 14008 14008
			  14008 14008 14008 14008 14008 14008 14008 14008 14008 14008 14008 14008 14008 14008 14008 14008
			  14008 14008 14008 14008 14008 14008 14008 14008 14008 14008 14008 14008 14008 14008 14008 14008
			  14008 14008 14008 14008 14008 14008 14008 14008 14008 14008 14008 14008 14008 14008 14008 14008
			  14008 14008 14008 14008 14008 14008 14008 14008 14008 14008 14008 14008 14008 14008 14008 14008
			  14008 14008 14008 14008 14008 14008 14008 14008 14008 14008 14008 14008 14008 14008 14008 14008
			  14008 14008 14008 14008 14008 14008 14008 14008 14008 14008 14008 14008 14008 14008 14008 14008
			  14008 14008 14008 14008 14008 14008 14008 14008 14008 14008 14008 14008 14008 14008 14008 14008
			  14008 14008 14008>;

			PS_Config_Lmt_Short_Rawdata_N = <
			  10100 10100 10100 10100 10100 10100 10100 10100 10100 10100 10100 10100 10100 10100 10100 10100
			  10100 10100 10100 10100 10100 10100 10100 10100 10100 10100 10100 10100 10100 10100 10100 10100
			  10100 10100 10100 10100 10100 10100 10100 10100 10100 10100 10100 10100 10100 10100 10100 10100
			  10100 10100 10100 10100 10100 10100 10100 10100 10100 10100 10100 10100 10100 10100 10100 10100
			  10100 10100 10100 10100 10100 10100 10100 10100 10100 10100 10100 10100 10100 10100 10100 10100
			  10100 10100 10100 10100 10100 10100 10100 10100 10100 10100 10100 10100 10100 10100 10100 10100
			  10100 10100 10100 10100 10100 10100 10100 10100 10100 10100 10100 10100 10100 10100 10100 10100
			  10100 10100 10100 10100 10100 10100 10100 10100 10100 10100 10100 10100 10100 10100 10100 10100
			  10100 10100 10100 10100 10100 10100 10100 10100 10100 10100 10100 10100 10100 10100 10100 10100
			  10100 10100 10100 10100 10100 10100 10100 10100 10100 10100 10100 10100 10100 10100 10100 10100
			  10100 10100 10100 10100 10100 10100 10100 10100 10100 10100 10100 10100 10100 10100 10100 10100
			  10100 10100 10100 10100 10100 10100 10100 10100 10100 10100 10100 10100 10100 10100 10100 10100
			  10100 10100 10100 10100 10100 10100 10100 10100 10100 10100 10100 10100 10100 10100 10100 10100
			  10100 10100 10100 10100 10100 10100 10100 10100 10100 10100 10100 10100 10100 10100 10100 10100
			  10100 10100 10100 10100 10100 10100 10100 10100 10100 10100 10100 10100 10100 10100 10100 10100
			  10100 10100 10100 10100 10100 10100 10100 10100 10100 10100 10100 10100 10100 10100 10100 10100
			  10100 10100 10100 10100 10100 10100 10100 10100 10100 10100 10100 10100 10100 10100 10100 10100
			  10100 10100 10100 10100 10100 10100 10100 10100 10100 10100 10100 10100 10100 10100 10100 10100
			  10100 10100 10100 10100 10100 10100 10100 10100 10100 10100 10100 10100 10100 10100 10100 10100
			  10100 10100 10100 10100 10100 10100 10100 10100 10100 10100 10100 10100 10100 10100 10100 10100
			  10100 10100 10100 10100 10100 10100 10100 10100 10100 10100 10100 10100 10100 10100 10100 10100
			  10100 10100 10100 10100 10100 10100 10100 10100 10100 10100 10100 10100 10100 10100 10100 10100
			  10100 10100 10100 10100 10100 10100 10100 10100 10100 10100 10100 10100 10100 10100 10100 10100
			  10100 10100 10100 10100 10100 10100 10100 10100 10100 10100 10100 10100 10100 10100 10100 10100
			  10100 10100 10100 10100 10100 10100 10100 10100 10100 10100 10100 10100 10100 10100 10100 10100
			  10100 10100 10100 10100 10100 10100 10100 10100 10100 10100 10100 10100 10100 10100 10100 10100
			  10100 10100 10100 10100 10100 10100 10100 10100 10100 10100 10100 10100 10100 10100 10100 10100
			  10100 10100 10100 10100 10100 10100 10100 10100 10100 10100 10100 10100 10100 10100 10100 10100
			  10100 10100 10100 10100 10100 10100 10100 10100 10100 10100 10100 10100 10100 10100 10100 10100
			  10100 10100 10100 10100 10100 10100 10100 10100 10100 10100 10100 10100 10100 10100 10100 10100
			  10100 10100 10100 10100 10100 10100 10100 10100 10100 10100 10100 10100 10100 10100 10100 10100
			  10100 10100 10100 10100 10100 10100 10100 10100 10100 10100 10100 10100 10100 10100 10100 10100
			  10100 10100 10100 10100 10100 10100 10100 10100 10100 10100 10100 10100 10100 10100 10100 10100
			  10100 10100 10100 10100 10100 10100 10100 10100 10100 10100 10100 10100 10100 10100 10100 10100
			  10100 10100 10100 10100 10100 10100 10100 10100 10100 10100 10100 10100 10100 10100 10100 10100
			  10100 10100 10100 10100 10100 10100 10100 10100 10100 10100 10100 10100 10100 10100 10100 10100
			  10000 10000 10000>;

			PS_Config_Lmt_Open_Rawdata_P = <
			  2816 2905 3078 3243 3298 3343 3406 3432 3364 3360 3294 3252 3179 3059 2882 2812
			  2920 2966 3141 3294 3343 3375 3369 3416 3327 3276 3271 3242 3194 3091 2923 2874
			  2944 2979 3154 3341 3432 3467 3525 3567 3463 3417 3358 3309 3221 3103 2940 2913
			  2962 2997 3180 3368 3434 3459 3491 3546 3451 3416 3374 3336 3280 3166 2989 2973
			  2956 2998 3169 3362 3455 3490 3544 3589 3467 3421 3367 3316 3229 3113 2965 2938
			  2986 3028 3194 3368 3442 3452 3508 3546 3407 3374 3343 3299 3242 3119 2993 2963
			  3001 3054 3243 3417 3516 3560 3619 3666 3518 3472 3409 3361 3297 3179 3035 2990
			  3004 3066 3246 3382 3458 3511 3546 3578 3414 3388 3341 3315 3243 3185 3056 3010
			  3021 3084 3257 3404 3536 3574 3626 3662 3473 3427 3376 3316 3266 3166 3039 3000
			  3053 3119 3298 3434 3556 3584 3630 3658 3453 3420 3382 3333 3297 3213 3091 3046
			  3026 3102 3253 3435 3563 3607 3654 3694 3514 3474 3400 3374 3308 3194 3059 3031
			  3057 3136 3297 3438 3553 3584 3616 3654 3439 3409 3367 3336 3290 3206 3081 3060
			  3071 3133 3336 3487 3641 3687 3736 3768 3526 3476 3445 3402 3333 3228 3088 3061
			  3070 3155 3330 3441 3579 3609 3642 3676 3449 3423 3382 3357 3305 3238 3119 3098
			  3036 3143 3320 3472 3628 3675 3721 3733 3473 3473 3424 3368 3301 3217 3088 3077
			  3110 3206 3383 3505 3659 3691 3735 3785 3508 3456 3421 3378 3327 3276 3154 3129
			  3085 3180 3341 3486 3655 3708 3764 3780 3487 3470 3416 3362 3302 3221 3103 3094
			  3098 3196 3346 3467 3626 3662 3712 3763 3462 3424 3365 3322 3274 3225 3113 3103
			  3005 3038 3120 3256 3330 3383 3452 3497 3731 3697 3628 3575 3400 3196 3064 2969
			  3024 3046 3124 3252 3305 3344 3390 3423 3658 3635 3581 3547 3400 3214 3089 3005
			  3003 3046 3124 3252 3327 3376 3442 3481 3696 3661 3596 3551 3389 3197 3084 2987
			  3064 3105 3190 3316 3365 3397 3455 3470 3687 3668 3609 3578 3446 3252 3127 3035
			  3021 3071 3154 3277 3362 3400 3466 3495 3673 3648 3589 3546 3383 3204 3078 2993
			  3045 3087 3164 3287 3333 3358 3416 3428 3628 3617 3571 3533 3411 3232 3102 3031
			  3028 3094 3193 3325 3389 3434 3507 3539 3703 3682 3610 3570 3432 3236 3089 3015
			  3053 3108 3201 3308 3360 3392 3444 3462 3612 3603 3543 3514 3403 3234 3091 3029
			  3024 3080 3189 3309 3385 3423 3497 3525 3661 3631 3558 3514 3402 3213 3068 3007
			  3066 3113 3234 3350 3407 3430 3494 3511 3647 3626 3567 3533 3438 3256 3102 3045
			  3036 3094 3208 3332 3397 3435 3508 3537 3635 3609 3540 3494 3399 3213 3050 3005
			  3042 3084 3207 3323 3372 3392 3458 3472 3574 3564 3507 3474 3402 3238 3067 3033
			  3039 3098 3252 3353 3416 3453 3532 3563 3652 3626 3544 3505 3423 3249 3068 3022
			  2942 2973 3108 3187 3248 3276 3320 3337 3389 3379 3320 3295 3235 3119 2961 2941
			  2935 2961 3109 3211 3281 3315 3379 3403 3458 3434 3371 3332 3267 3124 2954 2933
			  2814 3001 3155 3252 3313 3336 3393 3406 3456 3439 3389 3364 3315 3175 3012 2835
			  2795 2958 3117 3222 3302 3337 3397 3423 3451 3428 3368 3327 3245 3110 2942 2800
			  2854 2954 3131 3250 3309 3330 3397 3399 3411 3418 3348 3318 3263 3124 2945 2898
			  5120 5120 5120>;

			PS_Config_Lmt_Open_Rawdata_N = <
			  1207 1245 1319 1390 1413 1432 1459 1471 1441 1440 1411 1393 1362 1311 1235 1205
			  1251 1271 1346 1411 1432 1446 1444 1464 1426 1404 1402 1389 1369 1324 1252 1231
			  1261 1276 1351 1432 1471 1486 1510 1528 1484 1464 1439 1418 1380 1330 1260 1248
			  1269 1284 1363 1443 1471 1482 1496 1519 1479 1464 1446 1429 1405 1357 1281 1274
			  1267 1285 1358 1441 1480 1495 1519 1538 1486 1466 1443 1421 1384 1334 1270 1259
			  1279 1297 1369 1443 1475 1479 1503 1519 1460 1446 1432 1414 1389 1336 1282 1270
			  1286 1309 1390 1464 1507 1525 1551 1571 1507 1488 1461 1440 1413 1362 1300 1281
			  1287 1314 1391 1449 1482 1504 1519 1533 1463 1452 1432 1420 1390 1365 1309 1290
			  1294 1321 1396 1459 1515 1531 1554 1569 1488 1468 1447 1421 1399 1357 1302 1285
			  1308 1336 1413 1471 1524 1536 1555 1567 1480 1465 1449 1428 1413 1377 1324 1305
			  1297 1329 1394 1472 1527 1546 1566 1583 1506 1489 1457 1446 1417 1369 1311 1299
			  1310 1344 1413 1473 1522 1536 1549 1566 1474 1461 1443 1429 1410 1374 1320 1311
			  1316 1342 1429 1494 1560 1580 1601 1615 1511 1489 1476 1458 1428 1383 1323 1312
			  1315 1352 1427 1474 1534 1546 1561 1575 1478 1467 1449 1438 1416 1387 1336 1327
			  1301 1347 1423 1488 1555 1575 1594 1600 1488 1488 1467 1443 1414 1378 1323 1318
			  1333 1374 1450 1502 1568 1582 1600 1622 1503 1481 1466 1447 1426 1404 1351 1341
			  1322 1363 1432 1494 1566 1589 1613 1620 1494 1487 1464 1441 1415 1380 1330 1326
			  1327 1369 1434 1486 1554 1569 1591 1612 1483 1467 1442 1423 1403 1382 1334 1330
			  1288 1302 1337 1395 1427 1450 1479 1498 1599 1584 1555 1532 1457 1369 1313 1272
			  1296 1305 1339 1393 1416 1433 1453 1467 1567 1558 1534 1520 1457 1377 1324 1288
			  1287 1305 1339 1393 1426 1447 1475 1492 1584 1569 1541 1522 1452 1370 1321 1280
			  1313 1330 1367 1421 1442 1456 1480 1487 1580 1572 1546 1533 1477 1393 1340 1300
			  1294 1316 1351 1404 1441 1457 1485 1498 1574 1563 1538 1519 1450 1373 1319 1282
			  1305 1323 1356 1408 1428 1439 1464 1469 1555 1550 1530 1514 1462 1385 1329 1299
			  1297 1326 1368 1425 1452 1471 1503 1516 1587 1578 1547 1530 1471 1387 1324 1292
			  1308 1332 1372 1417 1440 1453 1476 1483 1548 1544 1518 1506 1458 1386 1324 1298
			  1296 1320 1366 1418 1450 1467 1498 1510 1569 1556 1525 1506 1458 1377 1315 1288
			  1314 1334 1386 1435 1460 1470 1497 1504 1563 1554 1528 1514 1473 1395 1329 1305
			  1301 1326 1375 1428 1456 1472 1503 1516 1558 1546 1517 1497 1456 1377 1307 1288
			  1303 1321 1374 1424 1445 1453 1482 1488 1531 1527 1503 1489 1458 1387 1314 1300
			  1302 1327 1393 1437 1464 1480 1513 1527 1565 1554 1519 1502 1467 1392 1315 1295
			  1261 1274 1332 1366 1392 1404 1423 1430 1452 1448 1423 1412 1386 1336 1269 1260
			  1258 1269 1332 1376 1406 1420 1448 1458 1482 1471 1444 1428 1400 1339 1266 1257
			  1206 1286 1352 1393 1420 1429 1454 1459 1481 1474 1452 1441 1420 1360 1291 1215
			  1198 1267 1336 1381 1415 1430 1456 1467 1479 1469 1443 1426 1390 1333 1261 1200
			  1223 1266 1342 1393 1418 1427 1456 1456 1462 1465 1435 1422 1398 1339 1262 1242
			  (-511) (-511) (-511)>;

			PS_Config_Lmt_FW_Rawdata_P = <
			  1100 1099 1113 1122 1127 1132 1125 1114 1138 1106 1110 1107 1113 1117 1111 1122
			  1110 1135 1128 1125 1129 1134 1134 1108 1132 1122 1128 1125 1124 1122 1125 1113
			  1101 1125 1118 1115 1121 1114 1111 1113 1101 1128 1125 1131 1122 1125 1134 1103
			  1118 1129 1115 1124 1124 1121 1122 1113 1134 1135 1127 1129 1122 1128 1127 1108
			  1104 1127 1128 1127 1124 1132 1131 1122 1127 1114 1115 1113 1111 1107 1107 1134
			  1101 1117 1125 1127 1122 1124 1128 1103 1114 1114 1108 1115 1113 1117 1114 1115
			  1107 1127 1131 1121 1125 1111 1114 1106 1115 1114 1110 1110 1113 1115 1118 1121
			  1122 1113 1122 1117 1118 1115 1122 1104 1131 1120 1136 1121 1136 1132 1131 1110
			  1101 1121 1114 1104 1101 1108 1108 1106 1108 1113 1127 1111 1113 1114 1110 1124
			  1115 1121 1124 1122 1121 1104 1107 1135 1122 1121 1125 1113 1120 1115 1115 1122
			  1128 1122 1115 1122 1121 1125 1122 1111 1115 1120 1127 1115 1124 1120 1118 1121
			  1110 1110 1106 1108 1110 1117 1117 1111 1107 1118 1121 1110 1114 1113 1113 1114
			  1110 1106 1108 1113 1113 1118 1117 1117 1128 1106 1104 1127 1118 1122 1129 1101
			  1114 1110 1117 1114 1115 1117 1117 1117 1117 1114 1118 1107 1115 1110 1108 1122
			  1096 1129 1121 1115 1129 1097 1099 1117 1125 1111 1110 1121 1113 1117 1120 1108
			  1113 1107 1110 1110 1113 1121 1122 1120 1107 1111 1108 1121 1128 1118 1121 1107
			  1117 1128 1128 1120 1104 1092 1096 1125 1118 1111 1115 1114 1114 1121 1117 1118
			  1115 1107 1115 1114 1124 1115 1114 1122 1117 1118 1121 1120 1115 1117 1118 1121
			  1103 1132 1124 1132 1135 1111 1111 1132 1099 1103 1107 1107 1124 1128 1122 1124
			  1121 1117 1113 1114 1115 1121 1121 1117 1115 1120 1128 1104 1104 1099 1097 1124
			  1124 1122 1117 1124 1120 1129 1127 1125 1115 1122 1110 1099 1104 1106 1106 1125
			  1127 1122 1115 1122 1118 1117 1122 1118 1110 1110 1121 1117 1115 1121 1117 1111
			  1100 1121 1118 1122 1117 1115 1104 1103 1099 1101 1115 1121 1125 1129 1128 1113
			  1107 1127 1114 1125 1118 1121 1124 1114 1106 1107 1113 1113 1121 1121 1122 1108
			  1124 1115 1104 1113 1106 1106 1124 1122 1128 1125 1107 1108 1114 1111 1111 1122
			  1108 1120 1110 1117 1111 1110 1117 1120 1110 1121 1134 1134 1135 1118 1115 1122
			  1122 1104 1104 1103 1107 1108 1113 1111 1118 1117 1101 1099 1104 1111 1117 1124
			  1117 1124 1120 1121 1125 1131 1122 1113 1127 1122 1108 1103 1101 1099 1110 1107
			  1114 1111 1114 1114 1117 1117 1117 1120 1108 1111 1127 1128 1122 1122 1118 1114
			  1118 1114 1108 1108 1113 1110 1122 1127 1107 1107 1114 1114 1121 1122 1127 1118
			  1110 1113 1115 1111 1111 1117 1122 1117 1120 1118 1111 1107 1118 1114 1121 1122
			  1115 1110 1114 1115 1118 1121 1120 1111 1110 1106 1118 1107 1138 1131 1131 1106
			  1111 1111 1110 1113 1124 1117 1120 1118 1118 1108 1108 1113 1114 1113 1121 1115
			  1114 1106 1104 1115 1106 1111 1103 1118 1117 1118 1118 1118 1115 1117 1114 1114
			  1104 1117 1117 1124 1117 1115 1110 1117 1117 1129 1115 1124 1113 1121 1121 1115
			  1121 1107 1103 1110 1110 1110 1121 1121 1138 1138 1138 1120 1108 1113 1120 1100
			  3840 3840 3840>;

			PS_Config_Lmt_FW_Rawdata_N = <
			  471 471 477 481 483 485 482 477 487 474 475 474 477 478 476 481
			  475 486 483 482 484 486 486 475 485 481 483 482 481 481 482 477
			  472 482 479 478 480 477 476 477 472 483 482 484 481 482 486 472
			  479 484 478 481 481 480 481 477 486 486 483 484 481 483 483 475
			  473 483 483 483 481 485 484 481 483 477 478 477 476 474 474 486
			  472 478 482 483 481 481 483 472 477 477 475 478 477 478 477 478
			  474 483 484 480 482 476 477 474 478 477 475 475 477 478 479 480
			  481 477 481 478 479 478 481 473 484 480 487 480 487 485 484 475
			  472 480 477 473 472 475 475 474 475 477 483 476 477 477 475 481
			  478 480 481 481 480 473 474 486 481 480 482 477 480 478 478 481
			  483 481 478 481 480 482 481 476 478 480 483 478 481 480 479 480
			  475 475 474 475 475 478 478 476 474 479 480 475 477 477 477 477
			  475 474 475 477 477 479 478 478 483 474 473 483 479 481 484 472
			  477 475 478 477 478 478 478 478 478 477 479 474 478 475 475 481
			  469 484 480 478 484 470 471 478 482 476 475 480 477 478 480 475
			  477 474 475 475 477 480 481 480 474 476 475 480 483 479 480 474
			  478 483 483 480 473 468 469 482 479 476 478 477 477 480 478 479
			  478 474 478 477 481 478 477 481 478 479 480 480 478 478 479 480
			  472 485 481 485 486 476 476 485 471 472 474 474 481 483 481 481
			  480 478 477 477 478 480 480 478 478 480 483 473 473 471 470 481
			  481 481 478 481 480 484 483 482 478 481 475 471 473 474 474 482
			  483 481 478 481 479 478 481 479 475 475 480 478 478 480 478 476
			  471 480 479 481 478 478 473 472 471 472 478 480 482 484 483 477
			  474 483 477 482 479 480 481 477 474 474 477 477 480 480 481 475
			  481 478 473 477 474 474 481 481 483 482 474 475 477 476 476 481
			  475 480 475 478 476 475 478 480 475 480 486 486 486 479 478 481
			  481 473 473 472 474 475 477 476 479 478 472 471 473 476 478 481
			  478 481 480 480 482 484 481 477 483 481 475 472 472 471 475 474
			  477 476 477 477 478 478 478 480 475 476 483 483 481 481 479 477
			  479 477 475 475 477 475 481 483 474 474 477 477 480 481 483 479
			  475 477 478 476 476 478 481 478 480 479 476 474 479 477 480 481
			  478 475 477 478 479 480 480 476 475 474 479 474 487 484 484 474
			  476 476 475 477 481 478 480 479 479 475 475 477 477 477 480 478
			  477 474 473 478 474 476 472 479 478 479 479 479 478 478 477 477
			  473 478 478 481 478 478 475 478 478 484 478 481 477 480 480 478
			  480 474 472 475 475 475 480 480 487 487 487 480 475 477 480 471
			  240 240 240>;

			PS_Config_Lmt_FW_CC_P = <
			  52 52 52 52 52 52 53 53 53 53 53 53 53 52 52 52
			  53 52 53 53 52 52 52 53 52 52 52 52 52 52 52 53
			  53 52 52 52 52 52 52 52 53 52 52 52 52 52 52 53
			  53 52 53 52 52 52 52 53 52 52 53 52 53 53 52 53
			  53 52 52 52 52 52 52 52 53 52 52 52 52 52 52 53
			  53 52 52 52 52 53 53 53 53 53 53 52 53 53 52 53
			  53 52 52 52 52 52 52 52 53 52 53 53 53 53 53 53
			  53 53 53 53 53 53 53 53 52 52 52 52 53 53 53 53
			  53 52 52 52 52 53 53 53 53 53 53 53 53 53 53 53
			  53 53 53 53 53 53 53 53 53 53 53 53 53 53 53 53
			  53 52 52 52 52 53 53 53 53 53 53 52 52 52 53 53
			  53 53 53 53 53 53 53 55 53 53 53 53 53 53 53 53
			  53 52 52 52 52 53 53 53 53 53 53 53 53 53 52 53
			  53 52 53 53 53 53 53 55 53 53 53 53 53 53 53 53
			  53 52 52 53 53 53 53 53 53 53 53 52 53 52 52 53
			  53 53 53 53 53 53 53 55 53 53 53 52 53 53 52 53
			  53 52 53 53 53 53 53 53 53 53 53 52 52 52 52 53
			  53 53 53 53 53 53 53 55 53 53 53 53 53 52 52 53
			  53 52 52 52 52 52 52 52 53 53 53 53 52 52 52 53
			  53 53 53 53 53 53 53 53 53 53 53 53 53 53 53 53
			  53 52 52 52 52 52 52 52 53 53 53 53 53 52 52 53
			  53 53 53 53 53 53 53 53 53 53 53 53 53 53 53 53
			  53 52 52 52 52 52 53 53 53 53 53 53 52 52 52 53
			  53 52 52 52 52 52 53 53 53 53 53 53 53 53 53 53
			  53 52 52 52 52 52 53 53 53 53 52 53 52 52 52 53
			  53 53 53 53 53 53 53 53 53 53 52 52 52 52 52 53
			  53 52 52 52 52 52 53 53 53 53 53 53 53 52 52 53
			  53 53 53 53 53 53 53 53 53 53 53 53 53 53 53 53
			  53 52 52 52 52 52 52 53 53 53 53 53 53 52 52 53
			  53 53 53 53 53 53 53 53 53 53 53 53 53 53 52 53
			  53 52 52 52 52 52 53 53 53 53 53 53 53 53 52 53
			  53 52 52 52 53 52 53 53 53 53 53 53 52 52 52 53
			  53 52 52 52 52 52 52 52 53 53 53 53 52 52 52 53
			  53 53 53 52 53 53 53 53 53 53 53 52 52 53 52 52
			  52 52 52 52 52 52 52 52 53 52 52 52 52 52 52 53
			  53 53 53 53 53 53 53 53 53 53 53 52 52 52 53 53
			  314 314 314>;

			PS_Config_Lmt_FW_CC_N = <
			  23 23 23 23 23 23 24 24 24 24 24 24 24 23 23 23
			  24 23 24 24 23 23 23 24 23 23 23 23 23 23 23 24
			  24 23 23 23 23 23 23 23 24 23 23 23 23 23 23 24
			  24 23 24 23 23 23 23 24 23 23 24 23 24 24 23 24
			  24 23 23 23 23 23 23 23 24 23 23 23 23 23 23 24
			  24 23 23 23 23 24 24 24 24 24 24 23 24 24 23 24
			  24 23 23 23 23 23 23 23 24 23 24 24 24 24 24 24
			  24 24 24 24 24 24 24 24 23 23 23 23 24 24 24 24
			  24 23 23 23 23 24 24 24 24 24 24 24 24 24 24 24
			  24 24 24 24 24 24 24 24 24 24 24 24 24 24 24 24
			  24 23 23 23 23 24 24 24 24 24 24 23 23 23 24 24
			  24 24 24 24 24 24 24 24 24 24 24 24 24 24 24 24
			  24 23 23 23 23 24 24 24 24 24 24 24 24 24 23 24
			  24 23 24 24 24 24 24 24 24 24 24 24 24 24 24 24
			  24 23 23 24 24 24 24 24 24 24 24 23 24 23 23 24
			  24 24 24 24 24 24 24 24 24 24 24 23 24 24 23 24
			  24 23 24 24 24 24 24 24 24 24 24 23 23 23 23 24
			  24 24 24 24 24 24 24 24 24 24 24 24 24 23 23 24
			  24 23 23 23 23 23 23 23 24 24 24 24 23 23 23 24
			  24 24 24 24 24 24 24 24 24 24 24 24 24 24 24 24
			  24 23 23 23 23 23 23 23 24 24 24 24 24 23 23 24
			  24 24 24 24 24 24 24 24 24 24 24 24 24 24 24 24
			  24 23 23 23 23 23 24 24 24 24 24 24 23 23 23 24
			  24 23 23 23 23 23 24 24 24 24 24 24 24 24 24 24
			  24 23 23 23 23 23 24 24 24 24 23 24 23 23 23 24
			  24 24 24 24 24 24 24 24 24 24 23 23 23 23 23 24
			  24 23 23 23 23 23 24 24 24 24 24 24 24 23 23 24
			  24 24 24 24 24 24 24 24 24 24 24 24 24 24 24 24
			  24 23 23 23 23 23 23 24 24 24 24 24 24 23 23 24
			  24 24 24 24 24 24 24 24 24 24 24 24 24 24 23 24
			  24 23 23 23 23 23 24 24 24 24 24 24 24 24 23 24
			  24 23 23 23 24 23 24 24 24 24 24 24 23 23 23 24
			  24 23 23 23 23 23 23 23 24 24 24 24 23 23 23 24
			  24 24 24 23 24 24 24 24 24 24 24 23 23 24 23 23
			  23 23 23 23 23 23 23 23 24 23 23 23 23 23 23 24
			  24 24 24 24 24 24 24 24 24 24 24 23 23 23 24 24
			  0 0 0>;

			PS_Config_Lmt_FW_Diff_P = <
			  50 50 50 50 50 50 50 50 50 50 50 50 50 50 50 50
			  50 50 50 50 50 50 50 50 50 50 50 50 50 50 50 50
			  50 50 50 50 50 50 50 50 50 50 50 50 50 50 50 50
			  50 50 50 50 50 50 50 50 50 50 50 50 50 50 50 50
			  50 50 50 50 50 50 50 50 50 50 50 50 50 50 50 50
			  50 50 50 50 50 50 50 50 50 50 50 50 50 50 50 50
			  50 50 50 50 50 50 50 50 50 50 50 50 50 50 50 50
			  50 50 50 50 50 50 50 50 50 50 50 50 50 50 50 50
			  50 50 50 50 50 50 50 50 50 50 50 50 50 50 50 50
			  50 50 50 50 50 50 50 50 50 50 50 50 50 50 50 50
			  50 50 50 50 50 50 50 50 50 50 50 50 50 50 50 50
			  50 50 50 50 50 50 50 50 50 50 50 50 50 50 50 50
			  50 50 50 50 50 50 50 50 50 50 50 50 50 50 50 50
			  50 50 50 50 50 50 50 50 50 50 50 50 50 50 50 50
			  50 50 50 50 50 50 50 50 50 50 50 50 50 50 50 50
			  50 50 50 50 50 50 50 50 50 50 50 50 50 50 50 50
			  50 50 50 50 50 50 50 50 50 50 50 50 50 50 50 50
			  50 50 50 50 50 50 50 50 50 50 50 50 50 50 50 50
			  50 50 50 50 50 50 50 50 50 50 50 50 50 50 50 50
			  50 50 50 50 50 50 50 50 50 50 50 50 50 50 50 50
			  50 50 50 50 50 50 50 50 50 50 50 50 50 50 50 50
			  50 50 50 50 50 50 50 50 50 50 50 50 50 50 50 50
			  50 50 50 50 50 50 50 50 50 50 50 50 50 50 50 50
			  50 50 50 50 50 50 50 50 50 50 50 50 50 50 50 50
			  50 50 50 50 50 50 50 50 50 50 50 50 50 50 50 50
			  50 50 50 50 50 50 50 50 50 50 50 50 50 50 50 50
			  50 50 50 50 50 50 50 50 50 50 50 50 50 50 50 50
			  50 50 50 50 50 50 50 50 50 50 50 50 50 50 50 50
			  50 50 50 50 50 50 50 50 50 50 50 50 50 50 50 50
			  50 50 50 50 50 50 50 50 50 50 50 50 50 50 50 50
			  50 50 50 50 50 50 50 50 50 50 50 50 50 50 50 50
			  50 50 50 50 50 50 50 50 50 50 50 50 50 50 50 50
			  50 50 50 50 50 50 50 50 50 50 50 50 50 50 50 50
			  50 50 50 50 50 50 50 50 50 50 50 50 50 50 50 50
			  50 50 50 50 50 50 50 50 50 50 50 50 50 50 50 50
			  50 50 50 50 50 50 50 50 50 50 50 50 50 50 50 50
			  75 75 75>;

			PS_Config_Lmt_FW_Diff_N = <
			  (-50) (-50) (-50) (-50) (-50) (-50) (-50) (-50) (-50) (-50) (-50) (-50) (-50) (-50) (-50) (-50)
			  (-50) (-50) (-50) (-50) (-50) (-50) (-50) (-50) (-50) (-50) (-50) (-50) (-50) (-50) (-50) (-50)
			  (-50) (-50) (-50) (-50) (-50) (-50) (-50) (-50) (-50) (-50) (-50) (-50) (-50) (-50) (-50) (-50)
			  (-50) (-50) (-50) (-50) (-50) (-50) (-50) (-50) (-50) (-50) (-50) (-50) (-50) (-50) (-50) (-50)
			  (-50) (-50) (-50) (-50) (-50) (-50) (-50) (-50) (-50) (-50) (-50) (-50) (-50) (-50) (-50) (-50)
			  (-50) (-50) (-50) (-50) (-50) (-50) (-50) (-50) (-50) (-50) (-50) (-50) (-50) (-50) (-50) (-50)
			  (-50) (-50) (-50) (-50) (-50) (-50) (-50) (-50) (-50) (-50) (-50) (-50) (-50) (-50) (-50) (-50)
			  (-50) (-50) (-50) (-50) (-50) (-50) (-50) (-50) (-50) (-50) (-50) (-50) (-50) (-50) (-50) (-50)
			  (-50) (-50) (-50) (-50) (-50) (-50) (-50) (-50) (-50) (-50) (-50) (-50) (-50) (-50) (-50) (-50)
			  (-50) (-50) (-50) (-50) (-50) (-50) (-50) (-50) (-50) (-50) (-50) (-50) (-50) (-50) (-50) (-50)
			  (-50) (-50) (-50) (-50) (-50) (-50) (-50) (-50) (-50) (-50) (-50) (-50) (-50) (-50) (-50) (-50)
			  (-50) (-50) (-50) (-50) (-50) (-50) (-50) (-50) (-50) (-50) (-50) (-50) (-50) (-50) (-50) (-50)
			  (-50) (-50) (-50) (-50) (-50) (-50) (-50) (-50) (-50) (-50) (-50) (-50) (-50) (-50) (-50) (-50)
			  (-50) (-50) (-50) (-50) (-50) (-50) (-50) (-50) (-50) (-50) (-50) (-50) (-50) (-50) (-50) (-50)
			  (-50) (-50) (-50) (-50) (-50) (-50) (-50) (-50) (-50) (-50) (-50) (-50) (-50) (-50) (-50) (-50)
			  (-50) (-50) (-50) (-50) (-50) (-50) (-50) (-50) (-50) (-50) (-50) (-50) (-50) (-50) (-50) (-50)
			  (-50) (-50) (-50) (-50) (-50) (-50) (-50) (-50) (-50) (-50) (-50) (-50) (-50) (-50) (-50) (-50)
			  (-50) (-50) (-50) (-50) (-50) (-50) (-50) (-50) (-50) (-50) (-50) (-50) (-50) (-50) (-50) (-50)
			  (-50) (-50) (-50) (-50) (-50) (-50) (-50) (-50) (-50) (-50) (-50) (-50) (-50) (-50) (-50) (-50)
			  (-50) (-50) (-50) (-50) (-50) (-50) (-50) (-50) (-50) (-50) (-50) (-50) (-50) (-50) (-50) (-50)
			  (-50) (-50) (-50) (-50) (-50) (-50) (-50) (-50) (-50) (-50) (-50) (-50) (-50) (-50) (-50) (-50)
			  (-50) (-50) (-50) (-50) (-50) (-50) (-50) (-50) (-50) (-50) (-50) (-50) (-50) (-50) (-50) (-50)
			  (-50) (-50) (-50) (-50) (-50) (-50) (-50) (-50) (-50) (-50) (-50) (-50) (-50) (-50) (-50) (-50)
			  (-50) (-50) (-50) (-50) (-50) (-50) (-50) (-50) (-50) (-50) (-50) (-50) (-50) (-50) (-50) (-50)
			  (-50) (-50) (-50) (-50) (-50) (-50) (-50) (-50) (-50) (-50) (-50) (-50) (-50) (-50) (-50) (-50)
			  (-50) (-50) (-50) (-50) (-50) (-50) (-50) (-50) (-50) (-50) (-50) (-50) (-50) (-50) (-50) (-50)
			  (-50) (-50) (-50) (-50) (-50) (-50) (-50) (-50) (-50) (-50) (-50) (-50) (-50) (-50) (-50) (-50)
			  (-50) (-50) (-50) (-50) (-50) (-50) (-50) (-50) (-50) (-50) (-50) (-50) (-50) (-50) (-50) (-50)
			  (-50) (-50) (-50) (-50) (-50) (-50) (-50) (-50) (-50) (-50) (-50) (-50) (-50) (-50) (-50) (-50)
			  (-50) (-50) (-50) (-50) (-50) (-50) (-50) (-50) (-50) (-50) (-50) (-50) (-50) (-50) (-50) (-50)
			  (-50) (-50) (-50) (-50) (-50) (-50) (-50) (-50) (-50) (-50) (-50) (-50) (-50) (-50) (-50) (-50)
			  (-50) (-50) (-50) (-50) (-50) (-50) (-50) (-50) (-50) (-50) (-50) (-50) (-50) (-50) (-50) (-50)
			  (-50) (-50) (-50) (-50) (-50) (-50) (-50) (-50) (-50) (-50) (-50) (-50) (-50) (-50) (-50) (-50)
			  (-50) (-50) (-50) (-50) (-50) (-50) (-50) (-50) (-50) (-50) (-50) (-50) (-50) (-50) (-50) (-50)
			  (-50) (-50) (-50) (-50) (-50) (-50) (-50) (-50) (-50) (-50) (-50) (-50) (-50) (-50) (-50) (-50)
			  (-50) (-50) (-50) (-50) (-50) (-50) (-50) (-50) (-50) (-50) (-50) (-50) (-50) (-50) (-50) (-50)
			  (-75) (-75) (-75)>;
			PS_Config_Diff_Test_Frame = <50>;
		};
	};
};

&pio {
	ctp_nt36672c_pins_default: pins_default {
	};
	ctp_nt36672c_spi_mode: spimode_default {
		pins_cmd_dat {
			pinmux = <PINMUX_GPIO30__FUNC_SPI1_MI>,
				<PINMUX_GPIO29__FUNC_SPI1_MO>,
				<PINMUX_GPIO27__FUNC_SPI1_CLK>,
				<PINMUX_GPIO28__FUNC_SPI1_CSB>;
			drive-strength = <2>;
		};
	};
};
/* TOUCH end */
